# ESP32-C2 register map
Vendor: ESPRESSIF SYSTEMS (SHANGHAI) CO., LTD.; Series: ESP32-C2; File version: 4
CPU: RV32IMC r0p0, little endian, no MPU, no FPU, 4 interrupt priority bits
Address unit: 32 bits
Registers are 32-bit, read-write, reset 0x0 unless marked. A register's access mark holds for its fields unless they carry their own. Offsets are from the block's base; [hi:lo] are bit positions; {n}, {i} and the like mark numbered series.

## LEDC — LED PWM (Pulse Width Modulation) Controller
Base 0x60019000
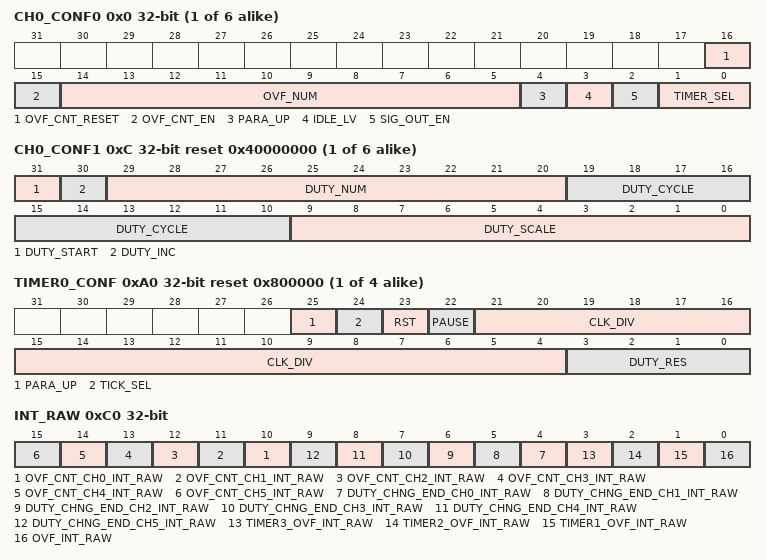
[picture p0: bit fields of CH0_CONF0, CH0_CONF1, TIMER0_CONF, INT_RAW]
{0x0+0x14*i} CH{i}_CONF0 (i=0..5) access per field — Configuration register 0 for channel {i}
  [16] OVF_CNT_RESET wo — Set this bit to reset the ovf_cnt of channel %s.
  [15] OVF_CNT_EN rw — This bit is used to enable the ovf_cnt of channel %s.
  [14:5] OVF_NUM rw — This register is used to configure the maximum times of overflow minus 1. The LEDC_OVF_CNT_CH%s_INT interrupt will be triggered when channel %s overflows for (LEDC_OVF_NUM_CH%s + 1) times.
  [4] PARA_UP wo — This bit is used to update LEDC_HPOINT_CH%s, LEDC_DUTY_START_CH%s, LEDC_SIG_OUT_EN_CH%s, LEDC_TIMER_SEL_CH%s, LEDC_DUTY_NUM_CH%s, LEDC_DUTY_CYCLE_CH%s, LEDC_DUTY_SCALE_CH%s, LEDC_DUTY_INC_CH%s, and LEDC_OVF_CNT_EN_CH%s fields for channel %s, and will be automatically cleared by hardware.
  [3] IDLE_LV rw — This bit is used to control the output value when channel %s is inactive (when LEDC_SIG_OUT_EN_CH%s is 0).
  [2] SIG_OUT_EN rw — Set this bit to enable signal output on channel %s.
  [1:0] TIMER_SEL rw — This field is used to select one of timers for channel %s. 0: select timer0; 1: select timer1; 2: select timer2; 3: select timer3
{0x4+0x14*i} CH{i}_HPOINT (i=0..5) — High point register for channel {i}
  [13:0] HPOINT — The output value changes to high when the selected timers has reached the value specified by this register.
{0x8+0x14*i} CH{i}_DUTY (i=0..5) — Initial duty cycle for channel {i}
  [18:0] DUTY — This register is used to change the output duty by controlling the Lpoint. The output value turns to low when the selected timers has reached the Lpoint.
{0xC+0x14*i} CH{i}_CONF1 (i=0..5) reset 0x40000000 — Configuration register 1 for channel {i}
  [31] DUTY_START — Other configured fields in LEDC_CH%s_CONF1_REG will start to take effect when this bit is set to 1.
  [30] DUTY_INC — This register is used to increase or decrease the duty of output signal on channel %s. 1: Increase; 0: Decrease.
  [29:20] DUTY_NUM — This register is used to control the number of times the duty cycle will be changed.
  [19:10] DUTY_CYCLE — The duty will change every LEDC_DUTY_CYCLE_CH%s on channel %s.
  [9:0] DUTY_SCALE — This register is used to configure the changing step scale of duty on channel %s.
{0x10+0x14*i} CH{i}_DUTY_R (i=0..5) ro — Current duty cycle for channel {i}
  [18:0] DUTY_CH0_R — This register stores the current duty of output signal on channel %s.
{0xA0+8i} TIMER{i}_CONF (i=0..3) access per field reset 0x800000 — Timer {i} configuration
  [25] PARA_UP wo — Set this bit to update LEDC_CLK_DIV_TIMER%s and LEDC_TIMER%s_DUTY_RES.
  [24] TICK_SEL rw — This bit is used to select clock for timer %s. When this bit is set to 1 LEDC_APB_CLK_SEL[1:0] should be 1, otherwise the timer clock may be not accurate. 1'h0: SLOW_CLK 1'h1: REF_TICK
  [23] RST rw — This bit is used to reset timer %s. The counter will show 0 after reset.
  [22] PAUSE rw — This bit is used to suspend the counter in timer %s.
  [21:4] CLK_DIV rw — This register is used to configure the divisor for the divider in timer %s. The least significant eight bits represent the fractional part.
  [3:0] DUTY_RES rw — This register is used to control the range of the counter in timer %s.
{0xA4+8i} TIMER{i}_VALUE (i=0..3) ro — Timer {i} current counter value
  [13:0] CNT — This register stores the current counter value of timer %s.
0xC0 INT_RAW ro — Raw interrupt status
  [n+10] OVF_CNT_CH{n}_INT_RAW (n=0..5) — Interrupt raw bit for channel {n}. Triggered when the ovf_cnt has reached the value specified by LEDC_OVF_NUM_CH{n}.
  [n+4] DUTY_CHNG_END_CH{n}_INT_RAW (n=0..5) — Interrupt raw bit for channel {n}. Triggered when the gradual change of duty has finished.
  [3] TIMER3_OVF_INT_RAW — Triggered when the timer3 has reached its maximum counter value.
  [2] TIMER2_OVF_INT_RAW — Triggered when the timer2 has reached its maximum counter value.
  [1] TIMER1_OVF_INT_RAW — Triggered when the timer1 has reached its maximum counter value.
  [0] OVF_INT_RAW — Triggered when the timer0 has reached its maximum counter value.
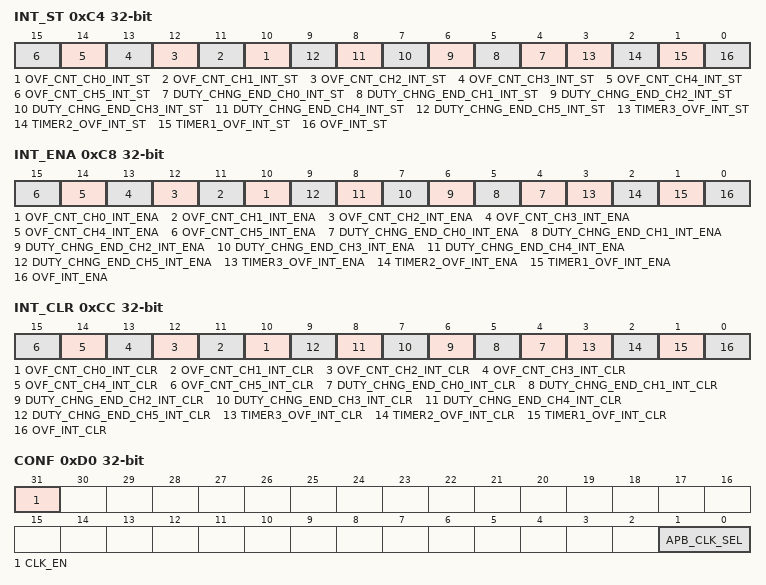
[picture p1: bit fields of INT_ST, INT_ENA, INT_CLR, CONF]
0xC4 INT_ST ro — Masked interrupt status
  [n+10] OVF_CNT_CH{n}_INT_ST (n=0..5) — This is the masked interrupt status bit for the LEDC_OVF_CNT_CH{n}_INT interrupt when LEDC_OVF_CNT_CH{n}_INT_ENA is set to 1.
  [n+4] DUTY_CHNG_END_CH{n}_INT_ST (n=0..5) — This is the masked interrupt status bit for the LEDC_DUTY_CHNG_END_CH{n}_INT interrupt when LEDC_DUTY_CHNG_END_CH{n}_INT_ENAIS set to 1.
  [3] TIMER3_OVF_INT_ST — This is the masked interrupt status bit for the LEDC_TIMER3_OVF_INT interrupt when LEDC_TIMER3_OVF_INT_ENA is set to 1.
  [2] TIMER2_OVF_INT_ST — This is the masked interrupt status bit for the LEDC_TIMER2_OVF_INT interrupt when LEDC_TIMER2_OVF_INT_ENA is set to 1.
  [1] TIMER1_OVF_INT_ST — This is the masked interrupt status bit for the LEDC_TIMER1_OVF_INT interrupt when LEDC_TIMER1_OVF_INT_ENA is set to 1.
  [0] OVF_INT_ST — This is the masked interrupt status bit for the LEDC_TIMER0_OVF_INT interrupt when LEDC_TIMER0_OVF_INT_ENA is set to 1.
0xC8 INT_ENA — Interrupt enable bits
  [n+10] OVF_CNT_CH{n}_INT_ENA (n=0..5) — The interrupt enable bit for the LEDC_OVF_CNT_CH{n}_INT interrupt.
  [n+4] DUTY_CHNG_END_CH{n}_INT_ENA (n=0..5) — The interrupt enable bit for the LEDC_DUTY_CHNG_END_CH{n}_INT interrupt.
  [3] TIMER3_OVF_INT_ENA — The interrupt enable bit for the LEDC_TIMER3_OVF_INT interrupt.
  [2] TIMER2_OVF_INT_ENA — The interrupt enable bit for the LEDC_TIMER2_OVF_INT interrupt.
  [1] TIMER1_OVF_INT_ENA — The interrupt enable bit for the LEDC_TIMER1_OVF_INT interrupt.
  [0] OVF_INT_ENA — The interrupt enable bit for the LEDC_TIMER0_OVF_INT interrupt.
0xCC INT_CLR wo — Interrupt clear bits
  [n+10] OVF_CNT_CH{n}_INT_CLR (n=0..5) — Set this bit to clear the LEDC_OVF_CNT_CH{n}_INT interrupt.
  [n+4] DUTY_CHNG_END_CH{n}_INT_CLR (n=0..5) — Set this bit to clear the LEDC_DUTY_CHNG_END_CH{n}_INT interrupt.
  [3] TIMER3_OVF_INT_CLR — Set this bit to clear the LEDC_TIMER3_OVF_INT interrupt.
  [2] TIMER2_OVF_INT_CLR — Set this bit to clear the LEDC_TIMER2_OVF_INT interrupt.
  [1] TIMER1_OVF_INT_CLR — Set this bit to clear the LEDC_TIMER1_OVF_INT interrupt.
  [0] OVF_INT_CLR — Set this bit to clear the LEDC_TIMER0_OVF_INT interrupt.
0xD0 CONF — Global ledc configuration register
  [31] CLK_EN — This bit is used to control clock. 1'b1: Force clock on for register. 1'h0: Support clock only when application writes registers.
  [1:0] APB_CLK_SEL — This bit is used to select clock source for the 4 timers . 2'd1: APB_CLK 2'd2: RTC8M_CLK 2'd3: XTAL_CLK
0xFC DATE reset 0x19061700 — Version control register
  [31:0] LEDC_DATE — This is the version control register.
